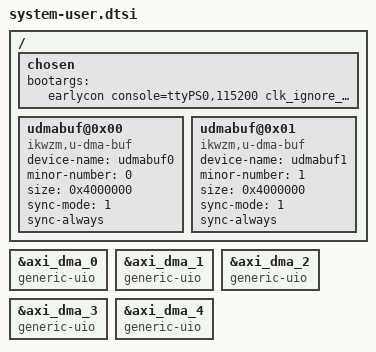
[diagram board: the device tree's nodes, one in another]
/include/ "system-conf.dtsi"
/ {
    chosen {
        bootargs = " earlycon console=ttyPS0,115200 clk_ignore_unused uio_pdrv_genirq.of_id=generic-uio root=/dev/ram0 rw";
    };

    udmabuf@0x00 {
        compatible = "ikwzm,u-dma-buf";
        device-name = "udmabuf0";
        minor-number = <0>;
        size = <0x4000000>;
        sync-mode = <1>;
        sync-always;
    };

    udmabuf@0x01 {
        compatible = "ikwzm,u-dma-buf";
        device-name = "udmabuf1";
        minor-number = <1>;
        size = <0x4000000>;
        sync-mode = <1>;
        sync-always;
    };
};

&axi_dma_0{
    compatible = "generic-uio";
};

&axi_dma_1{
    compatible = "generic-uio";
};

&axi_dma_2{
    compatible = "generic-uio";
};

&axi_dma_3{
    compatible = "generic-uio";
};

&axi_dma_4{
    compatible = "generic-uio";
};
